# HDSC_HC32L072PATA register map
Vendor: HDSC Co.Ltd; Series: ARMCM0P; File version: 1.2
CPU: CM0 r0p0, little endian, no MPU, no FPU, 3 interrupt priority bits
Registers are 32-bit, read-write, reset 0x0 unless marked. A register's access mark holds for its fields unless they carry their own. Offsets are from the block's base; [hi:lo] are bit positions; 'fields as' and 'values as' point back to an identical list.

## DEBUG_ACTIVE
Base 0x40002038
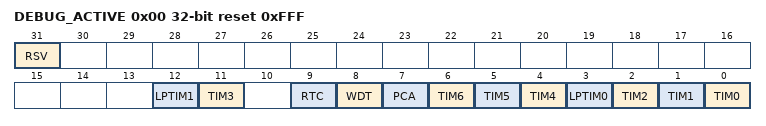
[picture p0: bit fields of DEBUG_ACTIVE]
0x00 DEBUG_ACTIVE reset 0xFFF (reset mask 0xFFF)
  [31] RSV, [12] LPTIM1, [11] TIM3, [9] RTC, [8] WDT, [7] PCA, [6] TIM6, [5] TIM5, [4] TIM4, [3] LPTIM0, [2] TIM2, [1] TIM1, [0] TIM0

## DMAC
Base 0x40021000
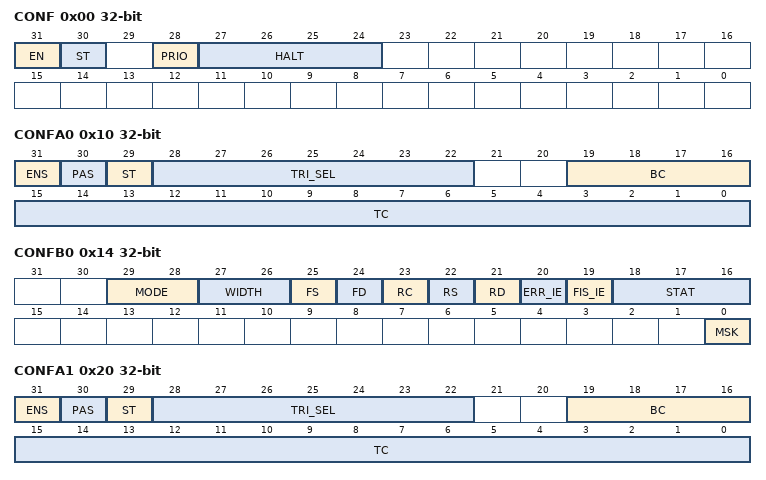
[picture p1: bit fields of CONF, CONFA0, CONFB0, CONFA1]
0x00 CONF
  [31] EN, [30] ST, [28] PRIO, [27:24] HALT
0x10 CONFA0 (reset mask 0xFF8FFFFF)
  [31] ENS, [30] PAS, [29] ST, [28:22] TRI_SEL, [19:16] BC, [15:0] TC
0x14 CONFB0
  [29:28] MODE, [27:26] WIDTH, [25] FS, [24] FD, [23] RC, [22] RS, [21] RD, [20] ERR_IE, [19] FIS_IE, [18:16] STAT, [0] MSK
0x18 SRCADR0
  [31:0] SRCADR
0x1C DSTADR0
  [31:0] DSTADR
0x20 CONFA1 (reset mask 0xFF8FFFFF)
  [31] ENS, [30] PAS, [29] ST, [28:22] TRI_SEL, [19:16] BC, [15:0] TC
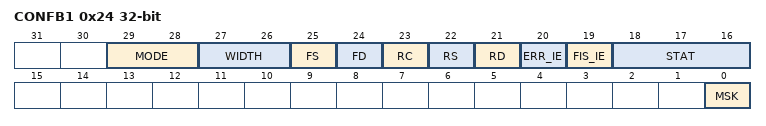
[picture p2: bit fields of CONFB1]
0x24 CONFB1
  fields as CONFB0
0x28 SRCADR1
  [31:0] SRCADR
0x2C DSTADR1
  [31:0] DSTADR

## FLASH
Base 0x40020000
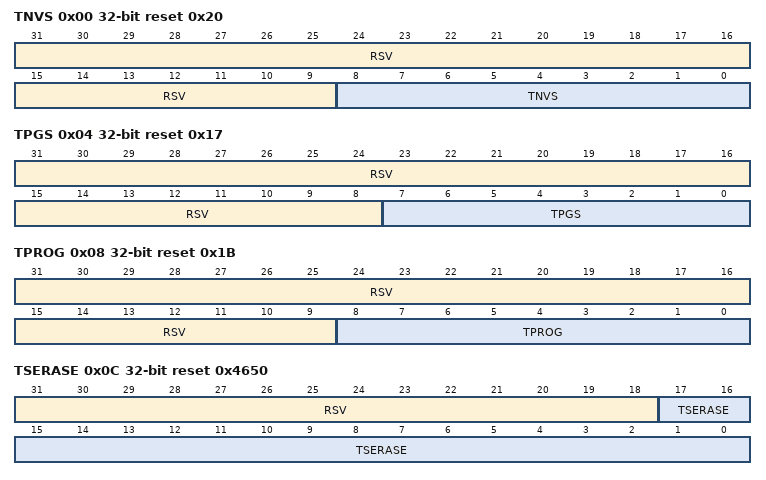
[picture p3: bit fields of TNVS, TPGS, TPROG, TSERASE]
0x00 TNVS reset 0x20 (reset mask 0x1FF)
  [31:9] RSV, [8:0] TNVS
0x04 TPGS reset 0x17 (reset mask 0xFF)
  [31:8] RSV, [7:0] TPGS
0x08 TPROG reset 0x1B (reset mask 0xFF)
  [31:9] RSV, [8:0] TPROG
0x0C TSERASE reset 0x4650 (reset mask 0x3FFFF)
  [31:18] RSV, [17:0] TSERASE
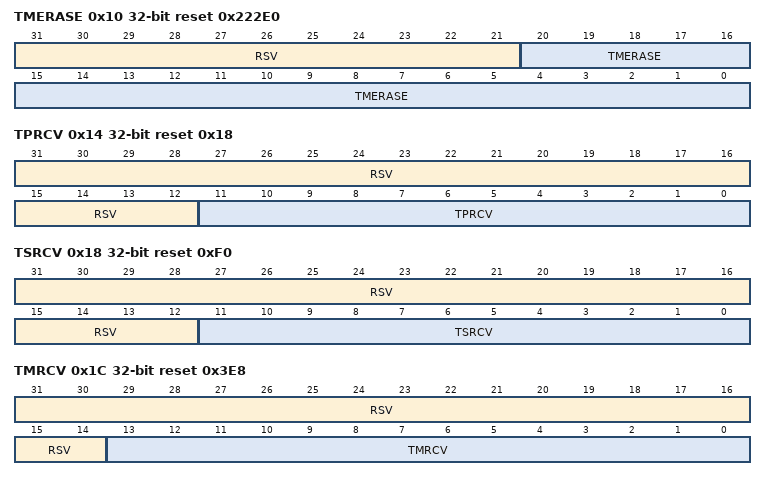
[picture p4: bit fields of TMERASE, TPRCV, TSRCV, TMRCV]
0x10 TMERASE reset 0x222E0 (reset mask 0x1FFFFF)
  [31:21] RSV, [20:0] TMERASE
0x14 TPRCV reset 0x18 (reset mask 0xFFF)
  [31:12] RSV, [11:0] TPRCV
0x18 TSRCV reset 0xF0 (reset mask 0xFFF)
  [31:12] RSV, [11:0] TSRCV
0x1C TMRCV reset 0x3E8 (reset mask 0x1FFF)
  [31:14] RSV, [13:0] TMRCV
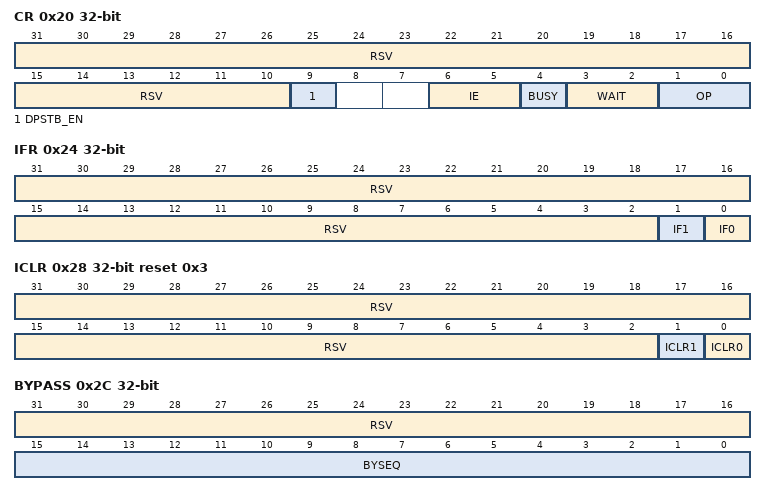
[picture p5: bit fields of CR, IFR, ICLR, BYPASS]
0x20 CR
  [31:10] RSV, [9] DPSTB_EN, [6:5] IE, [4] BUSY ro, [3:2] WAIT, [1:0] OP
0x24 IFR ro (reset mask 0x3)
  [31:2] RSV rw, [1] IF1, [0] IF0
0x28 ICLR wo reset 0x3
  [31:2] RSV rw, [1] ICLR1, [0] ICLR0
0x2C BYPASS wo (reset mask 0xFFFF)
  [31:16] RSV rw, [15:0] BYSEQ
0x30 SLOCK0
  [31:0] SLOCK
0x34 SLOCK1
  [31:0] SLOCK

## HDIV
Base 0x40021800
0x00 DIVIDEND
0x04 DIVISOR reset 0x1
  [15:0] DIVISOR
0x08 QUOTIENT
0x0C REMAINDER
0x10 SIGN
  [0] SIGN
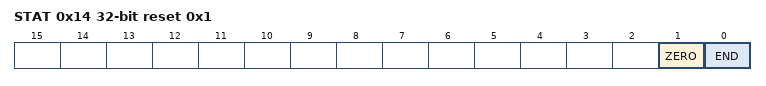
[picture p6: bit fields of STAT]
0x14 STAT reset 0x1
  [1] ZERO ro, [0] END ro

## I2C0 — desc I2C
Base 0x40000400
Same registers: I2C1 0x40004400
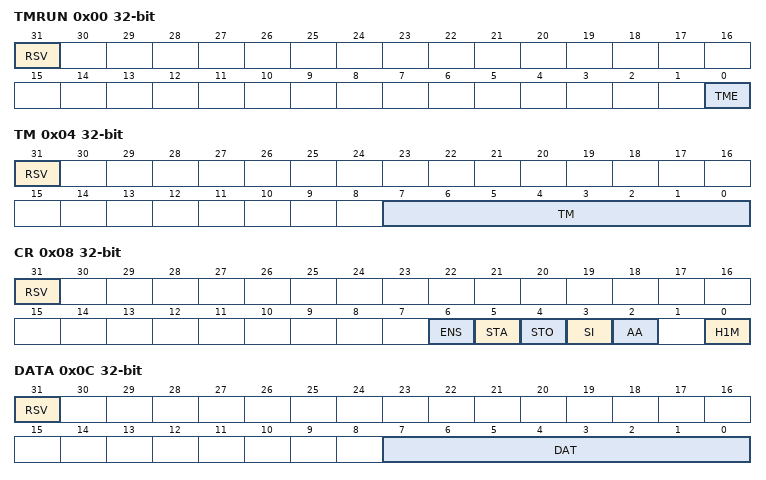
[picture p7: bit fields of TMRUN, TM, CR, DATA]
0x00 TMRUN (reset mask 0x1)
  [31] RSV, [0] TME
0x04 TM (reset mask 0xFF)
  [31] RSV, [7:0] TM
0x08 CR (reset mask 0x7D)
  [31] RSV, [6] ENS, [5] STA, [4] STO, [3] SI, [2] AA, [0] H1M
0x0C DATA (reset mask 0xFF)
  [31] RSV, [7:0] DAT
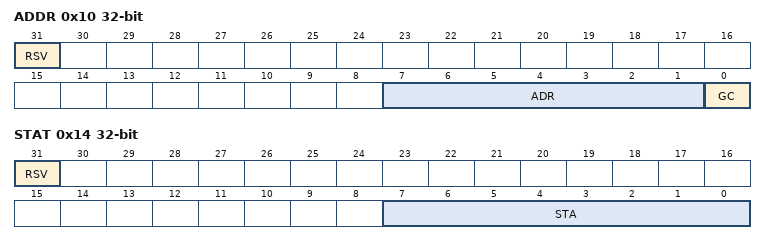
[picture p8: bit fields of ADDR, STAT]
0x10 ADDR (reset mask 0xFF)
  [31] RSV, [7:1] ADR, [0] GC
0x14 STAT ro (reset mask 0xFF)
  [31] RSV rw, [7:0] STA

## I2S0 — desc I2S
Base 0x40002800
Same registers: I2S1 0x40002C00
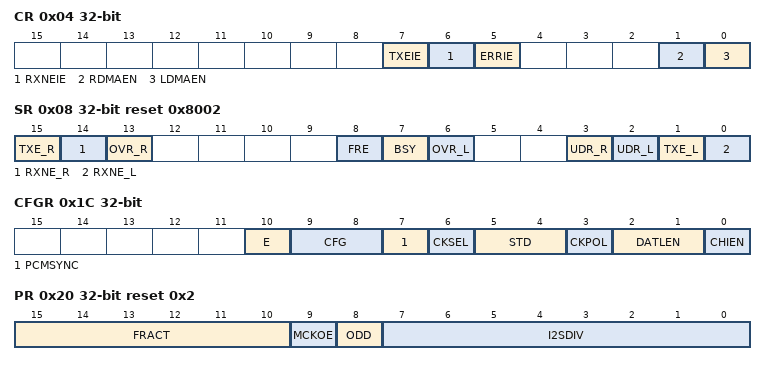
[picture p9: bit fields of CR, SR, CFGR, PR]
0x04 CR
  [7] TXEIE, [6] RXNEIE, [5] ERRIE, [1] RDMAEN, [0] LDMAEN
0x08 SR reset 0x8002
  [15] TXE_R ro, [14] RXNE_R ro, [13] OVR_R ro, [8] FRE ro, [7] BSY ro, [6] OVR_L ro, [3] UDR_R ro, [2] UDR_L ro, [1] TXE_L ro, [0] RXNE_L ro
0x1C CFGR
  [10] E, [9:8] CFG, [7] PCMSYNC, [6] CKSEL, [5:4] STD, [3] CKPOL, [2:1] DATLEN, [0] CHIEN
0x20 PR reset 0x2
  [15:10] FRACT, [9] MCKOE, [8] ODD, [7:0] I2SDIV
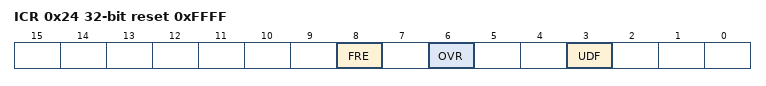
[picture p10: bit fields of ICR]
0x24 ICR reset 0xFFFF
  [8] FRE, [6] OVR, [3] UDF
0x28 DRL
  [15:0] DRL
0x2C DRR
  [15:0] DRR

## LPTIMER0 — desc LPTIMER
Base 0x40000F00
Same registers: LPTIMER1 0x40000F40
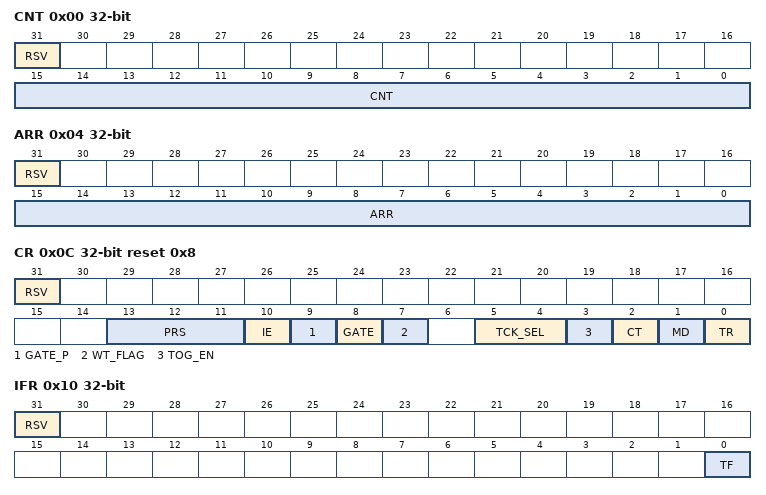
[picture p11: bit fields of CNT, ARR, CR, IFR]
0x00 CNT ro (reset mask 0xFFFF)
  [31] RSV rw, [15:0] CNT
0x04 ARR (reset mask 0xFFFF)
  [31] RSV, [15:0] ARR
0x0C CR reset 0x8 (reset mask 0x3FBF)
  [31] RSV, [13:11] PRS, [10] IE, [9] GATE_P, [8] GATE, [7] WT_FLAG ro, [5:4] TCK_SEL, [3] TOG_EN, [2] CT, [1] MD, [0] TR
0x10 IFR ro (reset mask 0x1)
  [31] RSV rw, [0] TF
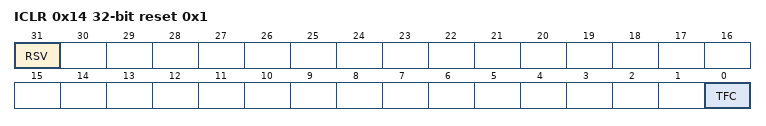
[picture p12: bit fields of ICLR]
0x14 ICLR wo reset 0x1 (reset mask 0x1)
  [31] RSV rw, [0] TFC

## LPUART0 — desc LPUART
Base 0x40000200
Same registers: LPUART1 0x40004000
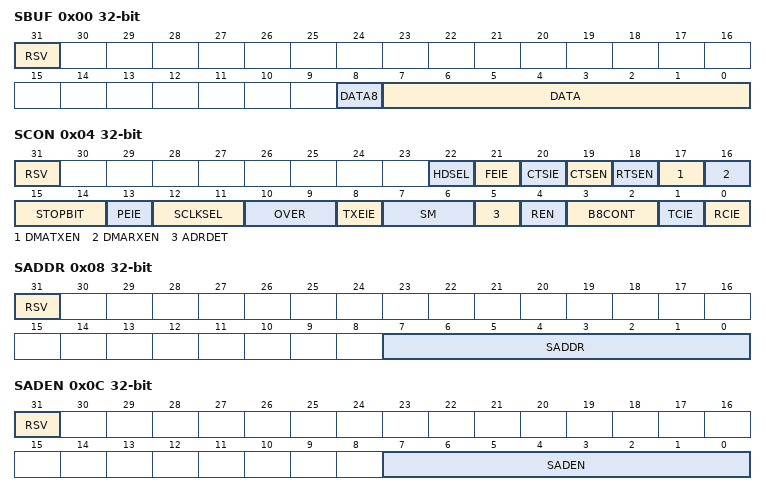
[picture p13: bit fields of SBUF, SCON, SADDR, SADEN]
0x00 SBUF (reset mask 0x1FF)
  [31] RSV, [8] DATA8, [7:0] DATA
0x04 SCON (reset mask 0x7FFFFF)
  [31] RSV, [22] HDSEL, [21] FEIE, [20] CTSIE, [19] CTSEN, [18] RTSEN, [17] DMATXEN, [16] DMARXEN, [15:14] STOPBIT, [13] PEIE, [12:11] SCLKSEL, [10:9] OVER, [8] TXEIE, [7:6] SM, [5] ADRDET, [4] REN, [3:2] B8CONT, [1] TCIE, [0] RCIE
0x08 SADDR (reset mask 0xFF)
  [31] RSV, [7:0] SADDR
0x0C SADEN (reset mask 0xFF)
  [31] RSV, [7:0] SADEN
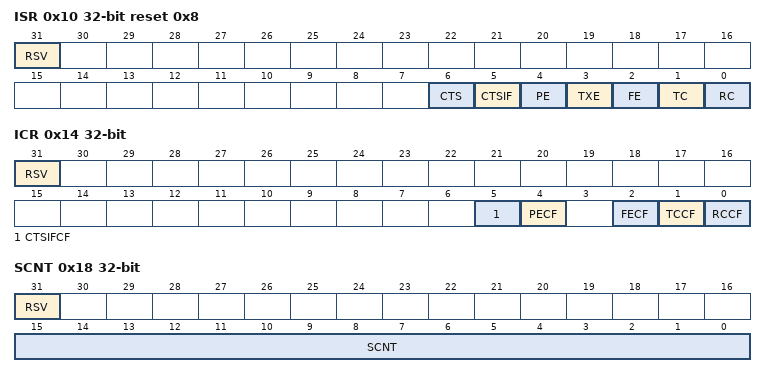
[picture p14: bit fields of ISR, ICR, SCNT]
0x10 ISR ro reset 0x8 (reset mask 0x7F)
  [31] RSV rw, [6] CTS, [5] CTSIF, [4] PE, [3] TXE, [2] FE, [1] TC, [0] RC
0x14 ICR wo (reset mask 0x37)
  [31] RSV rw, [5] CTSIFCF, [4] PECF, [2] FECF, [1] TCCF, [0] RCCF
0x18 SCNT (reset mask 0xFFFF)
  [31] RSV, [15:0] SCNT

## UART0 — desc UART
Base 0x40000000
Same registers: UART1 0x40000100, UART2 0x40006000, UART3 0x40006400
Registers as LPUART0; these are added or differ:
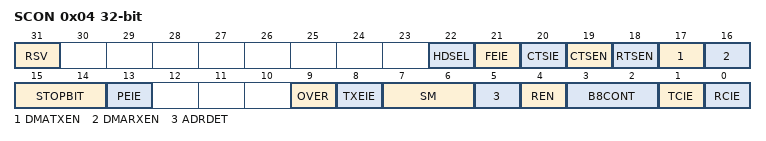
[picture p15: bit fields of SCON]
0x04 SCON (reset mask 0x7FE3FF)
  [31] RSV, [22] HDSEL, [21] FEIE, [20] CTSIE, [19] CTSEN, [18] RTSEN, [17] DMATXEN, [16] DMARXEN, [15:14] STOPBIT, [13] PEIE, [9] OVER, [8] TXEIE, [7:6] SM, [5] ADRDET, [4] REN, [3:2] B8CONT, [1] TCIE, [0] RCIE
